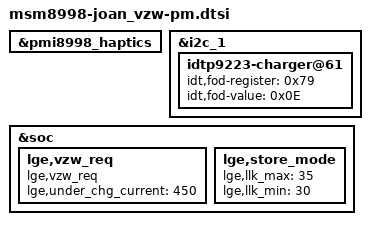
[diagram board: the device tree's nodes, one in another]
/* Copyright (c) 2016, The Linux Foundation. All rights reserved.
 *
 * This program is free software; you can redistribute it and/or modify
 * it under the terms of the GNU General Public License version 2 and
 * only version 2 as published by the Free Software Foundation.
 *
 * This program is distributed in the hope that it will be useful,
 * but WITHOUT ANY WARRANTY; without even the implied warranty of
 * MERCHANTABILITY or FITNESS FOR A PARTICULAR PURPOSE.  See the
 * GNU General Public License for more details.
 */

#include "../../msm8998-joan/msm8998-joan-common/msm8998-joan-common-pm.dtsi"

&pmi8998_haptics {
	status = "okay";
};

&i2c_1 { /* BLSP1 QUP1 */
	idtp9223-charger@61 {               /* Slave driver and slave Address */
		idt,fod-register = <0x79>;
		idt,fod-value = <0x0E>;
	};
};

&soc {
	lge,vzw_req {
		compatible = "lge,vzw_req";
		lge,under_chg_current = <450>;
	};

	lge,store_mode {
		lge,llk_max = <35>;
		lge,llk_min = <30>;
	};
};
